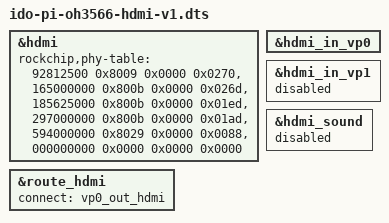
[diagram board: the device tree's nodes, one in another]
// SPDX-License-Identifier: (GPL-2.0+ OR MIT)
/*
 * Copyright (c) 2020 Rockchip Electronics Co., Ltd.
 *
 */

#include "ido-pi-oh3566-v1.dtsi"

&hdmi {
	status = "okay";
	rockchip,phy-table =
		<92812500  0x8009 0x0000 0x0270>,
		<165000000 0x800b 0x0000 0x026d>,
		<185625000 0x800b 0x0000 0x01ed>,
		<297000000 0x800b 0x0000 0x01ad>,
		<594000000 0x8029 0x0000 0x0088>,
		<000000000 0x0000 0x0000 0x0000>;
};

&hdmi_in_vp0 {
	status = "okay";
};

&hdmi_in_vp1 {
	status = "disabled";
};

&route_hdmi {
	status = "okay";
	connect = <&vp0_out_hdmi>;
};

&hdmi_sound {
	status = "disabled";
};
